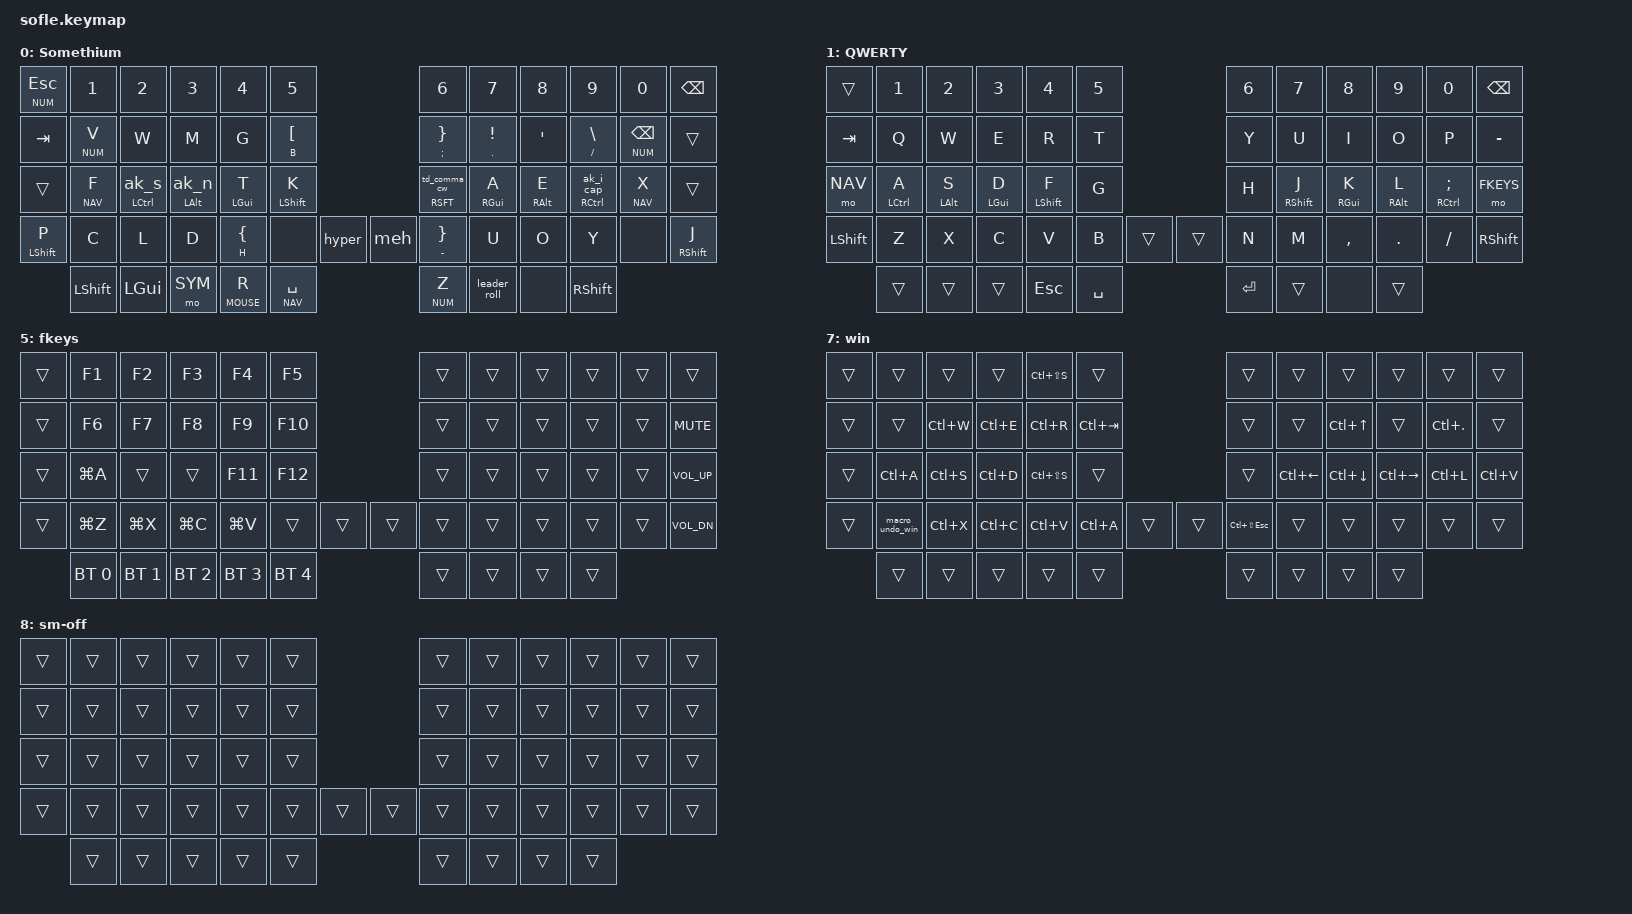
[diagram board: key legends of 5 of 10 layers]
/*
 * Profile: somethium
 * Hands Down Promethium (QMK Somethium 36-key) ported to Sofle Choc 60-key ZMK.
 * See docs/somethium-port.md for position mapping and parity notes.
 */

#include <behaviors.dtsi>
#include <dt-bindings/zmk/bt.h>
#include <dt-bindings/zmk/ext_power.h>
#include <dt-bindings/zmk/keys.h>
#define ZMK_POINTING_DEFAULT_SCRL_VAL 25
#include <dt-bindings/zmk/pointing.h>

#define SOMETHIUM 0
#define QWERTY    1
#define NAV       2
#define SYM       3
#define NUM       4
#define FKEYS     5
#define MOUSE     6
#define WIN       7
#define ADJUST    8
#define SM_OFF    9

// Mouse movement (195% of ZMK default 600 = 1170)
#ifndef KEYMAP_DRAWER
#define MOVE_UP_FAST    ((-1170) & 0xFFFF)
#define MOVE_DOWN_FAST  ((1170) & 0xFFFF)
#define MOVE_LEFT_FAST  (((-1170) & 0xFFFF) << 16)
#define MOVE_RIGHT_FAST (((1170) & 0xFFFF) << 16)

// Precision mouse movement (1/3 of fast speed)
#define MOVE_UP_SLOW    ((-390) & 0xFFFF)
#define MOVE_DOWN_SLOW  ((390) & 0xFFFF)
#define MOVE_LEFT_SLOW  (((-390) & 0xFFFF) << 16)
#define MOVE_RIGHT_SLOW (((390) & 0xFFFF) << 16)
#endif

/ {
    // Activate ADJUST layer by pressing NAV and NUMBERS together
    conditional_layers {
        compatible = "zmk,conditional-layers";

        adjust_layer {
            if-layers = <NAV NUM>;
            then-layer = <ADJUST>;
        };
    };

    combos {
        compatible = "zmk,combos";

        studio_unlock_combo {
            bindings = <&studio_unlock>;
            key-positions = <0 11>;
        };

        win_sc_combo_r {
            bindings = <&mo WIN>;
            key-positions = <34 35>;
            timeout-ms = <50>;
            slow-release;
        };

        win_sc_combo_l {
            bindings = <&mo WIN>;
            key-positions = <24 25>;
            timeout-ms = <50>;
            slow-release;
        };

        // ── Escape combos ─────────────────────────────────────────
        esc {
            bindings = <&kp ESCAPE>;
            key-positions = <25 41>;
        };

        esc2 {
            bindings = <&kp ESCAPE>;
            key-positions = <0 12>;
        };

        esc3 {
            bindings = <&kp ESCAPE>;
            key-positions = <0 1>;
        };

        // ── Thumb fat-finger protection ───────────────────────────
        thumb_fatfinger {
            bindings = <&kp ENTER>;
            key-positions = <54 55>;
        };

        thumb_fatfinger_left {
            bindings = <&kp SPACE>;
            key-positions = <52 53>;
        };

        thumb_fatfinger_right {
            bindings = <&kp SPACE>;
            key-positions = <56 57>;
        };

        numbers_toggle {
            bindings = <&tog NUM>;
            key-positions = <29 30>;
        };

        fatfinger_del_som {
            bindings = <&kp J>;
            key-positions = <41 42>;
            layers = <0>;
        };

        fatfinger_bksp_som {
            bindings = <&kp MINUS>;
            key-positions = <44 43>;
            layers = <0>;
        };

#include "somethium-combos.dtsi"
#include "somethium-assist-combos.dtsi"

    };

    macros {

#include "somethium-sm-macros.dtsi"
        hyper: hyper {
            compatible = "zmk,behavior-macro";
            #binding-cells = <0>;
            bindings
                = <&macro_press &kp LSHFT &kp LCTRL &kp LALT &kp LGUI>
                , <&macro_pause_for_release>
                , <&macro_release &kp LSHFT &kp LCTRL &kp LALT &kp LGUI>
                ;
        };

        hyper_space: hyper_space {
            compatible = "zmk,behavior-macro";
            #binding-cells = <0>;
            bindings
                = <&macro_press &kp LSHFT &kp LCTRL &kp LALT &kp LGUI>
                , <&macro_tap &kp SPACE>
                , <&macro_release &kp LSHFT &kp LCTRL &kp LALT &kp LGUI>
                ;
        };

        hyper_f: hyper_f {
            compatible = "zmk,behavior-macro";
            #binding-cells = <0>;
            bindings
                = <&macro_press &kp LSHFT &kp LCTRL &kp LALT &kp LGUI>
                , <&macro_tap &kp F>
                , <&macro_release &kp LSHFT &kp LCTRL &kp LALT &kp LGUI>
                ;
        };

        meh_f: meh_f {
            compatible = "zmk,behavior-macro";
            #binding-cells = <0>;
            bindings
                = <&macro_press &kp RSHFT &kp RCTRL &kp RALT>
                , <&macro_tap &kp F>
                , <&macro_release &kp RSHFT &kp RCTRL &kp RALT>
                ;
        };

        meh: meh {
            compatible = "zmk,behavior-macro";
            #binding-cells = <0>;
            bindings
                = <&macro_press &kp LSHFT &kp LCTRL &kp LALT>
                , <&macro_pause_for_release>
                , <&macro_release &kp LSHFT &kp LCTRL &kp LALT>
                ;
        };

        macro_undo: macro_undo {
            compatible = "zmk,behavior-macro";
            #binding-cells = <0>;
            wait-ms = <0>;
            tap-ms = <0>;
            bindings = <&kp LG(Z)>;
        };

        macro_undo_win: macro_undo_win {
            compatible = "zmk,behavior-macro";
            #binding-cells = <0>;
            wait-ms = <0>;
            tap-ms = <0>;
            bindings = <&kp LC(Z)>;
        };

        // ── N'T contraction macro ─────────────────────────────────
        nt_contraction: nt_contraction {
            compatible = "zmk,behavior-macro";
            #binding-cells = <0>;
            wait-ms = <0>;
            tap-ms = <0>;
            bindings = <&kp N &kp SQT &kp T>;
        };

        // ── QU digraph macros ─────────────────────────────────────
        qu_lower: qu_lower {
            compatible = "zmk,behavior-macro";
            #binding-cells = <0>;
            wait-ms = <0>;
            tap-ms = <0>;
            bindings = <&kp Q &kp U>;
        };

        qu_title: qu_title {
            compatible = "zmk,behavior-macro";
            #binding-cells = <0>;
            wait-ms = <0>;
            tap-ms = <0>;
            bindings
                = <&macro_press &kp LSHFT>
                , <&macro_tap &kp Q>
                , <&macro_release &kp LSHFT>
                , <&macro_tap &kp U>
                ;
        };

        // ── 'RE contraction macro ─────────────────────────────────
        re_contraction: re_contraction {
            compatible = "zmk,behavior-macro";
            #binding-cells = <0>;
            wait-ms = <0>;
            tap-ms = <0>;
            bindings = <&kp SQT &kp R &kp E>;
        };

        // ── Possessive/contraction macro ─────────────────────────
        ts_contraction: ts_contraction {
            compatible = "zmk,behavior-macro";
            #binding-cells = <0>;
            wait-ms = <0>;
            tap-ms = <0>;
            bindings = <&kp T &kp SQT &kp S>;
        };

        // ── SC digraph macro ──────────────────────────────────────
        sc_lower: sc_lower {
            compatible = "zmk,behavior-macro";
            #binding-cells = <0>;
            wait-ms = <0>;
            tap-ms = <0>;
            bindings = <&kp S &kp C>;
        };

        // ── KH digraph macro ──────────────────────────────────────
        kh_lower: kh_lower {
            compatible = "zmk,behavior-macro";
            #binding-cells = <0>;
            wait-ms = <0>;
            tap-ms = <0>;
            bindings = <&kp K &kp H>;
        };

        // ── Linger macros (hold = multi-char sequence) ─────────
        ck_linger: ck_linger {
            compatible = "zmk,behavior-macro";
            #binding-cells = <0>;
            wait-ms = <0>;
            tap-ms = <0>;
            bindings = <&kp C &kp K>;
        };

        fr_linger: fr_linger {
            compatible = "zmk,behavior-macro";
            #binding-cells = <0>;
            wait-ms = <0>;
            tap-ms = <0>;
            bindings = <&kp F &kp R>;
        };

        // ── H-digraph macros (lowercase) ────────────────────────
        th_lower: th_lower {
            compatible = "zmk,behavior-macro";
            #binding-cells = <0>;
            wait-ms = <0>;
            tap-ms = <0>;
            bindings = <&kp T &kp H>;
        };

        sh_lower: sh_lower {
            compatible = "zmk,behavior-macro";
            #binding-cells = <0>;
            wait-ms = <0>;
            tap-ms = <0>;
            bindings = <&kp S &kp H>;
        };

        ch_lower: ch_lower {
            compatible = "zmk,behavior-macro";
            #binding-cells = <0>;
            wait-ms = <0>;
            tap-ms = <0>;
            bindings = <&kp C &kp H>;
        };

        gh_lower: gh_lower {
            compatible = "zmk,behavior-macro";
            #binding-cells = <0>;
            wait-ms = <0>;
            tap-ms = <0>;
            bindings = <&kp G &kp H>;
        };

        ph_lower: ph_lower {
            compatible = "zmk,behavior-macro";
            #binding-cells = <0>;
            wait-ms = <0>;
            tap-ms = <0>;
            bindings = <&kp P &kp H>;
        };

        wh_lower: wh_lower {
            compatible = "zmk,behavior-macro";
            #binding-cells = <0>;
            wait-ms = <0>;
            tap-ms = <0>;
            bindings = <&kp W &kp H>;
        };

        // ── H-digraph macros (title case: Shift+combo → Th, Sh…)
        // First letter inherits held shift → uppercase,
        // then shift released so H comes out lowercase.
        // Title case macros: explicitly press shift for first letter, then release for H
        th_title: th_title {
            compatible = "zmk,behavior-macro";
            #binding-cells = <0>;
            wait-ms = <0>;
            tap-ms = <0>;
            bindings
                = <&macro_press &kp LSHFT>
                , <&macro_tap &kp T>
                , <&macro_release &kp LSHFT>
                , <&macro_tap &kp H>
                ;
        };

        sh_title: sh_title {
            compatible = "zmk,behavior-macro";
            #binding-cells = <0>;
            wait-ms = <0>;
            tap-ms = <0>;
            bindings
                = <&macro_press &kp LSHFT>
                , <&macro_tap &kp S>
                , <&macro_release &kp LSHFT>
                , <&macro_tap &kp H>
                ;
        };

        ch_title: ch_title {
            compatible = "zmk,behavior-macro";
            #binding-cells = <0>;
            wait-ms = <0>;
            tap-ms = <0>;
            bindings
                = <&macro_press &kp LSHFT>
                , <&macro_tap &kp C>
                , <&macro_release &kp LSHFT>
                , <&macro_tap &kp H>
                ;
        };

        gh_title: gh_title {
            compatible = "zmk,behavior-macro";
            #binding-cells = <0>;
            wait-ms = <0>;
            tap-ms = <0>;
            bindings
                = <&macro_press &kp LSHFT>
                , <&macro_tap &kp G>
                , <&macro_release &kp LSHFT>
                , <&macro_tap &kp H>
                ;
        };

        ph_title: ph_title {
            compatible = "zmk,behavior-macro";
            #binding-cells = <0>;
            wait-ms = <0>;
            tap-ms = <0>;
            bindings
                = <&macro_press &kp LSHFT>
                , <&macro_tap &kp P>
                , <&macro_release &kp LSHFT>
                , <&macro_tap &kp H>
                ;
        };

        wh_title: wh_title {
            compatible = "zmk,behavior-macro";
            #binding-cells = <0>;
            wait-ms = <0>;
            tap-ms = <0>;
            bindings
                = <&macro_press &kp LSHFT>
                , <&macro_tap &kp W>
                , <&macro_release &kp LSHFT>
                , <&macro_tap &kp H>
                ;
        };

        // ── Au+ word combos ──────────────────────────────────────
        word_with: word_with {
            compatible = "zmk,behavior-macro";
            #binding-cells = <0>;
            wait-ms = <0>;
            tap-ms = <0>;
            bindings = <&kp W &kp I &kp T &kp H>;
        };

        word_those: word_those {
            compatible = "zmk,behavior-macro";
            #binding-cells = <0>;
            wait-ms = <0>;
            tap-ms = <0>;
            bindings = <&kp T &kp H &kp O &kp S &kp E>;
        };

        word_this: word_this {
            compatible = "zmk,behavior-macro";
            #binding-cells = <0>;
            wait-ms = <0>;
            tap-ms = <0>;
            bindings = <&kp T &kp H &kp I &kp S>;
        };

        word_that: word_that {
            compatible = "zmk,behavior-macro";
            #binding-cells = <0>;
            wait-ms = <0>;
            tap-ms = <0>;
            bindings = <&kp T &kp H &kp A &kp T>;
        };

        // ── Prom short-word macros ──────────────────────────────
        word_the: word_the {
            compatible = "zmk,behavior-macro";
            #binding-cells = <0>;
            wait-ms = <0>;
            tap-ms = <0>;
            bindings = <&kp T &kp H &kp E>;
        };

        word_and: word_and {
            compatible = "zmk,behavior-macro";
            #binding-cells = <0>;
            wait-ms = <0>;
            tap-ms = <0>;
            bindings = <&kp A &kp N &kp D>;
        };

        word_of: word_of {
            compatible = "zmk,behavior-macro";
            #binding-cells = <0>;
            wait-ms = <0>;
            tap-ms = <0>;
            bindings = <&kp O &kp F>;
        };

        word_to: word_to {
            compatible = "zmk,behavior-macro";
            #binding-cells = <0>;
            wait-ms = <0>;
            tap-ms = <0>;
            bindings = <&kp T &kp O>;
        };

        word_in: word_in {
            compatible = "zmk,behavior-macro";
            #binding-cells = <0>;
            wait-ms = <0>;
            tap-ms = <0>;
            bindings = <&kp I &kp N>;
        };

        word_is: word_is {
            compatible = "zmk,behavior-macro";
            #binding-cells = <0>;
            wait-ms = <0>;
            tap-ms = <0>;
            bindings = <&kp I &kp S>;
        };

        word_for: word_for {
            compatible = "zmk,behavior-macro";
            #binding-cells = <0>;
            wait-ms = <0>;
            tap-ms = <0>;
            bindings = <&kp F &kp O &kp R>;
        };

        word_you: word_you {
            compatible = "zmk,behavior-macro";
            #binding-cells = <0>;
            wait-ms = <0>;
            tap-ms = <0>;
            bindings = <&kp Y &kp O &kp U>;
        };

        // ── Prom contraction macros ─────────────────────────────
        ll_contraction: ll_contraction {
            compatible = "zmk,behavior-macro";
            #binding-cells = <0>;
            wait-ms = <0>;
            tap-ms = <0>;
            bindings = <&kp SQT &kp L &kp L>;
        };

        ve_contraction: ve_contraction {
            compatible = "zmk,behavior-macro";
            #binding-cells = <0>;
            wait-ms = <0>;
            tap-ms = <0>;
            bindings = <&kp SQT &kp V &kp E>;
        };

        d_contraction: d_contraction {
            compatible = "zmk,behavior-macro";
            #binding-cells = <0>;
            wait-ms = <0>;
            tap-ms = <0>;
            bindings = <&kp SQT &kp D>;
        };

        m_contraction: m_contraction {
            compatible = "zmk,behavior-macro";
            #binding-cells = <0>;
            wait-ms = <0>;
            tap-ms = <0>;
            bindings = <&kp SQT &kp M>;
        };

        s_contraction: s_contraction {
            compatible = "zmk,behavior-macro";
            #binding-cells = <0>;
            wait-ms = <0>;
            tap-ms = <0>;
            bindings = <&kp SQT &kp S>;
        };
    };

    behaviors {

        hml: home_row_mod_left {
            compatible = "zmk,behavior-hold-tap";
            #binding-cells = <2>;
            flavor = "balanced";
            tapping-term-ms = <280>;
            quick-tap-ms = <175>;
            require-prior-idle-ms = <150>;
            bindings = <&kp>, <&kp>;
            hold-trigger-key-positions = <6 7 8 9 10 11 18 19 20 21 22 23 30 31 32 33 34 35 43 44 45 46 47 48 49 50 51 52 53 54 55 56 57 58 59>;
            hold-trigger-on-release;
        };

        hmr: home_row_mod_right {
            compatible = "zmk,behavior-hold-tap";
            #binding-cells = <2>;
            flavor = "balanced";
            tapping-term-ms = <280>;
            quick-tap-ms = <175>;
            require-prior-idle-ms = <150>;
            bindings = <&kp>, <&kp>;
            hold-trigger-key-positions = <0 1 2 3 4 5 12 13 14 15 16 17 24 25 26 27 28 29 36 37 38 39 40 41 42 50 51 52 53 54 55 56 57 58 59>;
            hold-trigger-on-release;
        };

        hml_g: home_row_mod_left_gui {
            compatible = "zmk,behavior-hold-tap";
            #binding-cells = <2>;
            flavor = "balanced";
            tapping-term-ms = <280>;
            quick-tap-ms = <175>;
            require-prior-idle-ms = <350>;
            bindings = <&kp>, <&kp>;
            hold-trigger-key-positions = <6 7 8 9 10 11 18 19 20 21 22 23 30 31 32 33 34 35 43 44 45 46 47 48 49 50 51 52 53 54 55 56 57 58 59>;
            hold-trigger-on-release;
        };

        hmr_g: home_row_mod_right_gui {
            compatible = "zmk,behavior-hold-tap";
            #binding-cells = <2>;
            flavor = "balanced";
            tapping-term-ms = <280>;
            quick-tap-ms = <175>;
            require-prior-idle-ms = <350>;
            bindings = <&kp>, <&kp>;
            hold-trigger-key-positions = <0 1 2 3 4 5 12 13 14 15 16 17 24 25 26 27 28 29 36 37 38 39 40 41 42 50 51 52 53 54 55 56 57 58 59>;
            hold-trigger-on-release;
        };

        lts: layer_tap_smart {
            compatible = "zmk,behavior-hold-tap";
            #binding-cells = <2>;
            flavor = "balanced";
            tapping-term-ms = <280>;
            quick-tap-ms = <175>;
            require-prior-idle-ms = <150>;
            bindings = <&mo>, <&kp>;
        };


        htk: hold_tap_kp {
            compatible = "zmk,behavior-hold-tap";
            #binding-cells = <2>;
            flavor = "balanced";
            tapping-term-ms = <200>;
            quick-tap-ms = <175>;
            bindings = <&kp>, <&kp>;
        };

        // ── Linger hold-taps: hold = macro, tap = key ─────────
        ht_c_ck: ht_c_ck {
            compatible = "zmk,behavior-hold-tap";
            #binding-cells = <2>;
            flavor = "balanced";
            tapping-term-ms = <200>;
            quick-tap-ms = <175>;
            bindings = <&ck_linger>, <&kp>;
        };

        ht_f_fr: ht_f_fr {
            compatible = "zmk,behavior-hold-tap";
            #binding-cells = <2>;
            flavor = "balanced";
            tapping-term-ms = <200>;
            quick-tap-ms = <175>;
            bindings = <&fr_linger>, <&kp>;
        };

        ht_w_wh: ht_w_wh {
            compatible = "zmk,behavior-hold-tap";
            #binding-cells = <2>;
            flavor = "balanced";
            tapping-term-ms = <200>;
            quick-tap-ms = <175>;
            bindings = <&wh_lower>, <&kp>;
        };

        ht_t_th: ht_t_th {
            compatible = "zmk,behavior-hold-tap";
            #binding-cells = <2>;
            flavor = "balanced";
            tapping-term-ms = <200>;
            quick-tap-ms = <175>;
            bindings = <&th_lower>, <&kp>;
        };

        // ── Magic H: adaptive key for Promethium ─────────────
        ak_h: ak_h {
            compatible = "zmk,behavior-adaptive-key";
            #binding-cells = <0>;
            bindings = <&kp H>;

            akt_ah { trigger-keys = <A>; max-prior-idle-ms = <300>; bindings = <&kp U>; };
            akt_eh { trigger-keys = <E>; max-prior-idle-ms = <300>; bindings = <&kp O>; };
            akt_oh { trigger-keys = <O>; max-prior-idle-ms = <300>; bindings = <&kp U>; };
            akt_uh { trigger-keys = <U>; max-prior-idle-ms = <300>; bindings = <&kp A>; };
            akt_ih { trigger-keys = <I>; max-prior-idle-ms = <300>; bindings = <&kp N &kp G>; };
        };

        // ── HRM wrapper for adaptive H on VF (hold=mod, tap=ak_h)
        hmr_ak_h: hmr_ak_h {
            compatible = "zmk,behavior-hold-tap";
            #binding-cells = <2>;
            flavor = "balanced";
            tapping-term-ms = <280>;
            quick-tap-ms = <175>;
            require-prior-idle-ms = <150>;
            bindings = <&kp>, <&ak_h>;
            hold-trigger-key-positions = <0 1 2 3 4 5 12 13 14 15 16 17 24 25 26 27 28 29 36 37 38 39 40 41 42 50 51 52 53 54 55 56 57 58 59>;
            hold-trigger-on-release;
        };

        // ── Hold-tap wrapper for adaptive H on thumb (hold=layer, tap=ak_h)
        lts_ak_h: lts_ak_h {
            compatible = "zmk,behavior-hold-tap";
            #binding-cells = <2>;
            flavor = "balanced";
            tapping-term-ms = <280>;
            quick-tap-ms = <175>;
            require-prior-idle-ms = <150>;
            bindings = <&mo>, <&ak_h>;
            hold-trigger-on-release;
        };

        // ── NAV hold / Caps Word tap ─────────────────────────────
        nav_cw: nav_cw {
            compatible = "zmk,behavior-hold-tap";
            #binding-cells = <2>;
            flavor = "balanced";
            tapping-term-ms = <280>;
            quick-tap-ms = <175>;
            bindings = <&mo>, <&caps_word>;
        };

        // ── Adaptive S: comma then S quickly = 's (magic comma)
        ak_s: ak_s {
            compatible = "zmk,behavior-adaptive-key";
            #binding-cells = <0>;
            bindings = <&kp S>;

            akt_comma_s { trigger-keys = <COMMA>; max-prior-idle-ms = <300>; bindings = <&kp BSPC &kp SQT &kp S>; };
        };

        // ── Adaptive R: comma then R quickly = 'r
        ak_r: ak_r {
            compatible = "zmk,behavior-adaptive-key";
            #binding-cells = <0>;
            bindings = <&kp R>;

            akt_comma_r { trigger-keys = <COMMA>; max-prior-idle-ms = <300>; bindings = <&kp BSPC &kp SQT &kp R>; };
        };

        // ── Adaptive T: comma then T quickly = 't
        ak_t: ak_t {
            compatible = "zmk,behavior-adaptive-key";
            #binding-cells = <0>;
            bindings = <&kp T>;

            akt_comma_t { trigger-keys = <COMMA>; max-prior-idle-ms = <300>; bindings = <&kp BSPC &kp SQT &kp T>; };
        };

        // ── Layer-tap wrapper for adaptive R (hold=layer, tap=ak_r)
        lts_ak_r: lts_ak_r {
            compatible = "zmk,behavior-hold-tap";
            #binding-cells = <2>;
            flavor = "balanced";
            tapping-term-ms = <280>;
            quick-tap-ms = <175>;
            require-prior-idle-ms = <150>;
            bindings = <&mo>, <&ak_r>;
            hold-trigger-on-release;
        };

        // ── HRM wrapper for adaptive T (hold=SHIFT, tap=ak_t)
        hml_ak_t: hml_ak_t {
            compatible = "zmk,behavior-hold-tap";
            #binding-cells = <2>;
            flavor = "balanced";
            tapping-term-ms = <280>;
            quick-tap-ms = <175>;
            require-prior-idle-ms = <150>;
            bindings = <&kp>, <&ak_t>;
            hold-trigger-key-positions = <6 7 8 9 10 11 18 19 20 21 22 23 30 31 32 33 34 35 43 44 45 46 47 48 49 50 51 52 53 54 55 56 57 58 59>;
            hold-trigger-on-release;
        };

        // ── HRM wrapper for adaptive N (hold=ALT, tap=ak_n)
        hml_ak_n: hml_ak_n {
            compatible = "zmk,behavior-hold-tap";
            #binding-cells = <2>;
            flavor = "balanced";
            tapping-term-ms = <280>;
            quick-tap-ms = <175>;
            require-prior-idle-ms = <150>;
            bindings = <&kp>, <&ak_n>;
            hold-trigger-key-positions = <6 7 8 9 10 11 18 19 20 21 22 23 30 31 32 33 34 35 43 44 45 46 47 48 49 50 51 52 53 54 55 56 57 58 59>;
            hold-trigger-on-release;
        };

        // ── HRM wrapper for adaptive S (hold=ALT, tap=ak_s)
        hml_ak_s: hml_ak_s {
            compatible = "zmk,behavior-hold-tap";
            #binding-cells = <2>;
            flavor = "balanced";
            tapping-term-ms = <280>;
            quick-tap-ms = <175>;
            require-prior-idle-ms = <150>;
            bindings = <&kp>, <&ak_s>;
            hold-trigger-key-positions = <6 7 8 9 10 11 18 19 20 21 22 23 30 31 32 33 34 35 43 44 45 46 47 48 49 50 51 52 53 54 55 56 57 58 59>;
            hold-trigger-on-release;
        };

        // ── Adaptive N: C then N quickly = "k" (for VF ck shortcut)
        ak_n: ak_n {
            compatible = "zmk,behavior-adaptive-key";
            #binding-cells = <0>;
            bindings = <&kp N>;

            akt_cn { trigger-keys = <C>; max-prior-idle-ms = <300>; bindings = <&kp K>; };
            akt_tn { trigger-keys = <T>; max-prior-idle-ms = <300>; bindings = <&kp I &kp O &kp N>; };
        };

        // ── HRM wrapper for adaptive N (hold=GUI, tap=ak_n)
        hml_g_ak_n: hml_g_ak_n {
            compatible = "zmk,behavior-hold-tap";
            #binding-cells = <2>;
            flavor = "balanced";
            tapping-term-ms = <280>;
            quick-tap-ms = <175>;
            require-prior-idle-ms = <350>;
            bindings = <&kp>, <&ak_n>;
            hold-trigger-key-positions = <6 7 8 9 10 11 18 19 20 21 22 23 30 31 32 33 34 35 43 44 45 46 47 48 49 50 51 52 53 54 55 56 57 58 59>;
            hold-trigger-on-release;
        };

        swap_app: swap_app {
            compatible = "zmk,behavior-tri-state";
            #binding-cells = <0>;
            bindings = <&kp LGUI>, <&kp TAB>, <&kp LGUI>;
            ignored-layers = <NAV WIN>;
        };

        swap_win: swap_win {
            compatible = "zmk,behavior-tri-state";
            #binding-cells = <0>;
            bindings = <&kp LGUI>, <&kp GRAVE>, <&kp LGUI>;
            ignored-layers = <NAV WIN>;
        };

        hmr_comma: home_row_mod_comma {
            compatible = "zmk,behavior-hold-tap";
            #binding-cells = <2>;
            flavor = "balanced";
            tapping-term-ms = <280>;
            quick-tap-ms = <175>;
            require-prior-idle-ms = <150>;
            bindings = <&kp>, <&td_comma_cw>;
            hold-trigger-key-positions = <0 1 2 3 4 5 12 13 14 15 16 17 24 25 26 27 28 29 36 37 38 39 40 41 42 50 51 52 53 54 55 56 57 58 59>;
            hold-trigger-on-release;
        };

        hmr_i: home_row_mod_i {
            compatible = "zmk,behavior-hold-tap";
            #binding-cells = <2>;
            flavor = "balanced";
            tapping-term-ms = <280>;
            quick-tap-ms = <175>;
            require-prior-idle-ms = <150>;
            bindings = <&kp>, <&ak_i_cap>;
            hold-trigger-key-positions = <0 1 2 3 4 5 12 13 14 15 16 17 24 25 26 27 28 29 36 37 38 39 40 41 42 50 51 52 53 54 55 56 57 58 59>;
            hold-trigger-on-release;
        };

        td_enc_l: tap_dance_enc_left {
            compatible = "zmk,behavior-tap-dance";
            #binding-cells = <0>;
            tapping-term-ms = <200>;
            bindings = <&none>, <&hyper_f>;
        };

        td_enc_r: tap_dance_enc_right {
            compatible = "zmk,behavior-tap-dance";
            #binding-cells = <0>;
            tapping-term-ms = <200>;
            bindings = <&none>, <&meh_f>;
        };

#include "somethium-sm-behaviors.dtsi"

    };

    keymap {
        compatible = "zmk,keymap";

        somethium_layer {
            display-name = "Somethium";

            bindings = <
&lts NUM ESC    &kp N1          &kp N2          &kp N3          &kp N4          &kp N5                                          &kp N6              &kp N7          &kp N8          &kp N9          &kp N0              &kp BSPC
&kp TAB         &lts NUM V      &kp W           &kp M           &kp G           &htk B LBKT                                     &htk SCLN RBRC    &htk DOT EXCL   &kp SQT         &htk FSLH BSLH  &lts NUM BSPC   &trans
&trans          &lts NAV F      &hml_ak_s LCTRL 0 &hml_ak_n LALT 0 &hml_g LGUI T    &hmr LSHFT K                                &hmr_comma RSFT 0 &hmr_g RGUI A    &hmr RALT E      &hmr_i RCTRL 0 &lts NAV X       &trans
&hmr LSHFT P    &kp C           &kp L           &kp D           &htk H LBRC     &none               &hyper              &meh                &htk MINUS RBRC   &kp U           &kp O           &kp Y           &none               &mt RIGHT_SHIFT J
                &kp LSHFT       &kp LGUI        &mo SYM         &lts MOUSE R    &lts NAV SPACE                                  &lts NUM Z      &leader_roll    &none           &kp RSHFT
            >;

            sensor-bindings = <&inc_dec_kp C_VOL_UP C_VOL_DN &inc_dec_kp PG_UP PG_DN>;
        };

        qwerty_layer {
            display-name = "QWERTY";

            bindings = <
&trans          &kp N1          &kp N2          &kp N3          &kp N4          &kp N5                                          &kp N6              &kp N7          &kp N8          &kp N9          &kp N0              &kp BSPC
&kp TAB         &kp Q           &kp W           &kp E           &kp R           &kp T                                           &kp Y               &kp U           &kp I           &kp O           &kp P               &kp MINUS
&mo NAV         &hml LCTRL A    &hml LALT S     &hml_g LGUI D   &hml LSHFT F    &kp G                                           &kp H               &hmr RSHFT J    &hmr_g RGUI K   &hmr RALT L     &hmr RCTRL SEMI     &mo FKEYS
&kp LSHFT       &kp Z           &kp X           &kp C           &kp V           &kp B           &trans              &trans      &kp N               &kp M           &kp COMMA       &kp DOT         &kp FSLH            &kp RSHFT
                &trans          &trans          &trans          &kp ESC         &kp SPACE                                       &kp ENTER       &trans          &none           &trans
            >;

            sensor-bindings = <&inc_dec_kp C_VOL_UP C_VOL_DN &inc_dec_kp PG_UP PG_DN>;
        };

        nav_layer {
            display-name = "nav";

            bindings = <
&trans          &trans          &trans          &trans          &trans          &trans                                          &trans              &trans          &trans          &trans          &trans              &kp DELETE
&swap_win       &trans          &trans          &trans          &trans          &trans                                          &kp PG_UP           &kp UP          &kp PGDN        &kp LG(LBKT)    &kp LG(RBKT)
&swap_app       &kp LCTRL       &kp LALT        &kp LGUI        &trans          &trans                                          &kp HOME            &kp LEFT        &kp DOWN        &kp RIGHT       &kp C_VOL_DN
&mt LSHFT &macro_undo &kp LG(X) &kp LG(C) &kp LG(V) &kp LG(A) &trans          &trans              &trans      &kp END             &msc SCRL_UP    &trans          &msc SCRL_DOWN  &kp C_VOL_UP
                &trans          &trans          &trans          &kp ENTER       &kp ENTER                                       &mkp LCLK           &mkp MCLK       &mkp RCLK
            >;

            sensor-bindings = <&inc_dec_kp C_VOL_UP C_VOL_DN &inc_dec_kp PG_UP PG_DN>;
        };

        sym_layer {
            display-name = "sym";

            bindings = <
&trans          &kp GRAVE       &kp TILDE       &kp AT          &kp HASH        &kp DLLR                                        &kp PRCNT           &kp CARET       &kp AMPS        &kp ASTRK       &kp BSLH            &trans
&trans          &kp UNDERSCORE  &kp MINUS       &kp PLUS        &kp EQUAL       &kp PIPE                                        &kp LPAR            &kp RPAR        &kp LBKT        &kp RBKT        &kp SEMI            &trans
&trans          &kp LT          &kp GT          &kp COLON       &kp DQT         &kp SQT                                         &kp LBRC            &kp RBRC        &kp FSLH        &kp QUESTION    &kp EXCL            &trans
&trans          &trans          &trans          &trans          &trans          &trans          &trans              &trans      &trans              &trans          &trans          &trans          &trans              &trans
                &trans          &trans          &trans          &trans          &trans                                          &trans              &trans          &trans
            >;

            sensor-bindings = <&inc_dec_kp C_VOL_UP C_VOL_DN &inc_dec_kp PG_UP PG_DN>;
        };

        num_layer {
            display-name = "num";

            bindings = <
&trans          &kp EXCL         &kp AT          &kp HASH        &kp DLLR        &kp PRCNT                                       &trans              &trans          &trans          &trans          &trans              &trans
&trans          &kp N1           &kp N2          &kp N3          &kp N4          &kp N5                                          &kp ASTRK           &kp N7          &kp N8          &kp N9          &trans              &trans
&trans          &kp N6           &kp N7          &kp N8          &kp N9          &kp N0                                          &kp MINUS           &kp N4          &kp N5          &kp N6          &trans              &trans
&trans          &kp CARET        &kp AMPS        &kp ASTRK       &kp LPAR        &kp RPAR        &trans              &trans      &kp PLUS            &kp N1          &kp N2          &kp N3          &trans              &trans
                &trans          &trans          &trans          &trans          &trans                                          &kp ENTER           &kp SPACE       &kp N0          &kp DOT         &kp ENTER
            >;

            sensor-bindings = <&inc_dec_kp C_VOL_UP C_VOL_DN &inc_dec_kp PG_UP PG_DN>;
        };

        fkeys_layer {
            display-name = "fkeys";

            bindings = <
&trans          &kp F1          &kp F2          &kp F3          &kp F4          &kp F5                                          &trans              &trans          &trans          &trans          &trans              &trans
&trans          &kp F6          &kp F7          &kp F8          &kp F9          &kp F10                                         &trans              &trans          &trans          &trans          &trans              &kp C_MUTE
&trans          &kp LG(A)       &trans          &trans          &kp F11         &kp F12                                         &trans              &trans          &trans          &trans          &trans              &kp C_VOL_UP
&trans          &kp LG(Z)       &kp LG(X)       &kp LG(C)       &kp LG(V)       &trans          &trans              &trans      &trans              &trans          &trans          &trans          &trans              &kp C_VOL_DN
                &bt BT_SEL 0    &bt BT_SEL 1    &bt BT_SEL 2    &bt BT_SEL 3    &bt BT_SEL 4                                    &trans              &trans          &trans          &trans
            >;

            sensor-bindings = <&inc_dec_kp C_VOL_UP C_VOL_DN &inc_dec_kp PG_UP PG_DN>;
        };

        mouse_layer {
            display-name = "mouse";

            bindings = <
&none          &none           &none           &none           &none           &none                                           &none               &none               &none                &none                &none          &none
&none          &none           &none           &none           &none           &none                                           &none               &msc SCRL_UP        &mmv MOVE_UP_FAST    &msc SCRL_DOWN       &none          &none
&none          &kp LCTRL       &kp LALT        &kp LSHFT       &kp LGUI        &none                                           &none               &mmv MOVE_LEFT_FAST &mmv MOVE_DOWN_FAST  &mmv MOVE_RIGHT_FAST &none          &none
&none          &none           &none           &none           &none           &none           &tog MOUSE      &tog MOUSE      &none               &none               &none                &none                &none          &none
               &none           &none           &none           &none           &kp ENTER                                       &kp ENTER           &mkp LCLK           &mkp RCLK            &mkp MCLK            &none
            >;

            sensor-bindings = <&inc_dec_kp C_VOL_UP C_VOL_DN &inc_dec_kp PG_UP PG_DN>;
        };

        win_layer {
            display-name = "win";

            bindings = <
&trans          &trans          &trans          &trans          &kp LC(LS(S))   &trans                                          &trans              &trans          &trans          &trans          &trans              &trans
&trans          &trans          &kp LC(W)       &kp LC(E)       &kp LC(R)       &kp LC(TAB)                                     &trans              &trans          &kp LC(UP)      &trans          &kp LC(DOT)         &trans
&trans          &kp LC(A)       &kp LC(S)       &kp LC(D)       &kp LC(LS(S))   &trans                                          &trans              &kp LC(LEFT)    &kp LC(DOWN)    &kp LC(RIGHT)   &kp LC(L)           &kp LC(V)
&trans          &macro_undo_win &kp LC(X)       &kp LC(C)       &kp LC(V)       &kp LC(A)       &trans              &trans      &kp LC(LS(ESC))     &trans          &trans          &trans          &trans              &trans
                &trans          &trans          &trans          &trans          &trans                                          &trans              &trans          &trans          &trans
            >;

            sensor-bindings = <&inc_dec_kp C_VOL_UP C_VOL_DN &inc_dec_kp PG_UP PG_DN>;
        };

        sm_off_layer {
            display-name = "sm-off";

            bindings = <
&trans          &trans          &trans          &trans          &trans          &trans                                          &trans              &trans          &trans          &trans          &trans              &trans
&trans          &trans          &trans          &trans          &trans          &trans                                          &trans              &trans          &trans          &trans          &trans              &trans
&trans          &trans          &trans          &trans          &trans          &trans                                          &trans              &trans          &trans          &trans          &trans              &trans
&trans          &trans          &trans          &trans          &trans          &trans          &trans              &trans      &trans              &trans          &trans          &trans          &trans              &trans
                &trans          &trans          &trans          &trans          &trans                                          &trans              &trans          &trans          &trans
            >;

            sensor-bindings = <&inc_dec_kp C_VOL_UP C_VOL_DN &inc_dec_kp PG_UP PG_DN>;
        };

        adjust_layer {
            display-name = "adjust";

            bindings = <
&bt BT_CLR_ALL  &bt BT_SEL 0    &bt BT_SEL 1    &bt BT_SEL 2    &bt BT_SEL 3    &bt BT_SEL 4                                    &bt BT_CLR          &none           &none           &none           &none               &none
&ext_power EP_TOG &none        &none           &none           &none           &studio_unlock                                  &none               &none           &none           &none           &none               &none
&none           &none           &none           &none           &none           &tog QWERTY                                     &tog MOUSE          &tog SM_OFF     &none           &none               &none
&none           &none           &none           &none           &none           &none           &none               &none      &none               &none           &none           &none           &none               &none
                &none           &none           &none           &none           &none                                           &none               &none           &none           &none
            >;

            sensor-bindings = <&inc_dec_kp C_VOL_UP C_VOL_DN &inc_dec_kp PG_UP PG_DN>;
        };

    };
};
